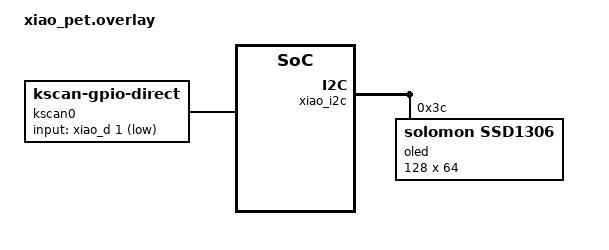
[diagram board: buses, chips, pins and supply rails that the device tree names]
#include <zephyr/dt-bindings/gpio/gpio.h>
#include <zephyr/dt-bindings/i2c/i2c.h>

/ {
    chosen {
        zmk,kscan = &kscan0;
        zephyr,display = &oled;
    };

    kscan0: kscan {
        compatible = "zmk,kscan-gpio-direct";
        input-gpios = <&xiao_d 1 (GPIO_ACTIVE_LOW | GPIO_PULL_UP)>;
    };
};

&xiao_i2c {
    status = "okay";

    oled: ssd1306@3c {
        compatible = "solomon,ssd1306";
        reg = <0x3c>;

        width = <128>;
        height = <64>;
        segment-offset = <0>;
        page-offset = <0>;
        display-offset = <0>;
        multiplex-ratio = <63>;

        segment-remap;
        com-invdir;
        prechargep = <0x22>;
    };
};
